# COMPUTE_CLUSTER_J7AHP0_C71SS0_0_AW4_DRU_DRU_SET register map
Vendor: Texas Instruments
Peripheral module from a debugger description file (folder J7_AHP).
Registers are 64-bit, write-only, reset 0x0 unless marked. A register's access mark holds for its fields unless they carry their own. Offsets are as the file gives them; lines under a group give offsets from that group; [hi:lo] are bit positions; {n}, {i} and the like mark numbered series; 'fields as' and 'values as' point back to an identical list; <NAME> marks a mode.

## COMPUTE_CLUSTER_J7AHP0_C71SS0_0_AW4_DRU_DRU_SET
0x00 AW4_DRU_DRU_SET_dru_shared_evt_set
  [0] PROT_ERR — Set the Prot Error event
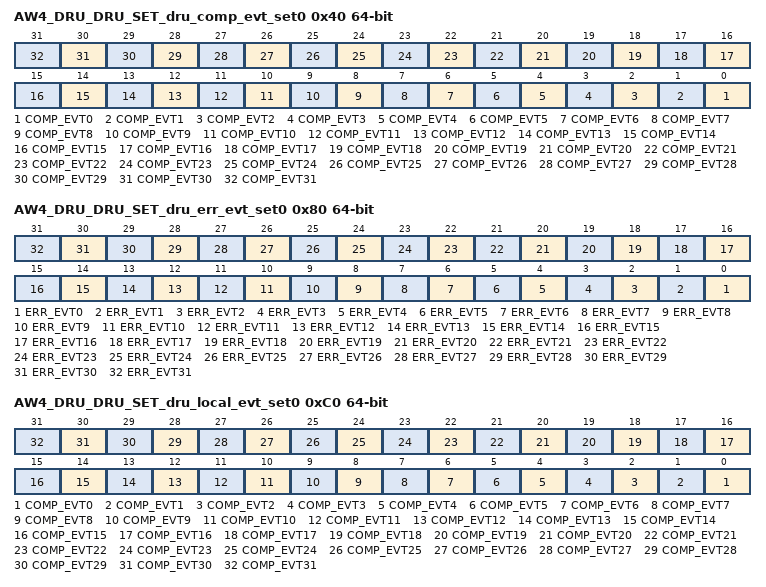
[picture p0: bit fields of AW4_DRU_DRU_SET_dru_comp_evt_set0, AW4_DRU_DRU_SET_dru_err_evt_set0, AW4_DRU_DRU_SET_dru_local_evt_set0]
0x40 AW4_DRU_DRU_SET_dru_comp_evt_set0
  [n] COMP_EVT{n} (n=0..31) — Set the Completion Event for channel {n}
0x80 AW4_DRU_DRU_SET_dru_err_evt_set0
  [n] ERR_EVT{n} (n=0..31) — Set the Error Event for channel {n}
0xC0 AW4_DRU_DRU_SET_dru_local_evt_set0
  [n] COMP_EVT{n} (n=0..31) — Set the Local Event for channel {n}
